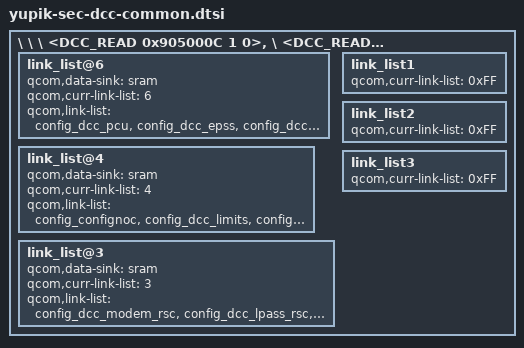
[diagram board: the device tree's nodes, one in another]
/* Copyright (c) 2019, The Linux Foundation. All rights reserved.
 *
 * This program is free software; you can redistribute it and/or modify
 * it under the terms of the GNU General Public License version 2 and
 * only version 2 as published by the Free Software Foundation.
 *
 * This program is distributed in the hope that it will be useful,
 * but WITHOUT ANY WARRANTY; without even the implied warranty of
 * MERCHANTABILITY or FITNESS FOR A PARTICULAR PURPOSE.  See the
 * GNU General Public License for more details.
 */

#include <dt-bindings/soc/qcom,dcc_v2.h>


#define config_dcc_pcu \
    /* PCU -DCC for LPM path */ \
    /*   Read only registers */ \
	<DCC_READ 0x18000010 1 0>, \
	<DCC_READ 0x18000024 1 0>, \
	<DCC_READ 0x18000038 6 0>, \
	<DCC_READ 0x18010010 1 0>, \
	<DCC_READ 0x18010024 1 0>, \
	<DCC_READ 0x18010038 6 0>, \
	<DCC_READ 0x18020010 1 0>, \
	<DCC_READ 0x18020024 1 0>, \
	<DCC_READ 0x18020038 6 0>, \
	<DCC_READ 0x18030010 1 0>, \
	<DCC_READ 0x18030024 1 0>, \
	<DCC_READ 0x18030038 6 0>, \
	<DCC_READ 0x18040010 1 0>, \
	<DCC_READ 0x18040024 1 0>, \
	<DCC_READ 0x18040038 6 0>, \
	<DCC_READ 0x18050010 1 0>, \
	<DCC_READ 0x18050024 1 0>, \
	<DCC_READ 0x18050038 6 0>, \
	<DCC_READ 0x18060010 1 0>, \
	<DCC_READ 0x18060024 1 0>, \
	<DCC_READ 0x18060038 6 0>, \
	<DCC_READ 0x18070010 1 0>, \
	<DCC_READ 0x18070024 1 0>, \
	<DCC_READ 0x18070038 6 0>, \
	<DCC_READ 0x18080010 1 0>, \
	<DCC_READ 0x18080024 1 0>, \
	<DCC_READ 0x18080038 6 0>, \
	<DCC_READ 0x1808006C 5 0>, \
	<DCC_READ 0x18080084 1 0>, \
	<DCC_READ 0x180800F4 1 0>, \
	<DCC_READ 0x180800F8 1 0>, \
	<DCC_READ 0x180800FC 1 0>, \
	<DCC_READ 0x18080100 12 0>, \
	<DCC_READ 0x18080130 3 0>, \
	<DCC_READ 0x18080158 1 0>, \
	<DCC_READ 0x1808015C 1 0>, \
	<DCC_READ 0x18080160 1 0>, \
	<DCC_READ 0x18080164 1 0>, \
	<DCC_READ 0x18080168 1 0>, \
	<DCC_READ 0x18080170 1 0>, \
	<DCC_READ 0x18080174 1 0>, \
	<DCC_READ 0x18080188 1 0>, \
	<DCC_READ 0x1808018C 1 0>, \
	<DCC_READ 0x18080190 1 0>, \
	<DCC_READ 0x18080194 1 0>, \
	<DCC_READ 0x18080198 1 0>, \
	<DCC_READ 0x180801AC 1 0>, \
	<DCC_READ 0x180801B0 4 0>, \
	<DCC_READ 0x180801C0 1 0>, \
	<DCC_READ 0x180801C8 1 0>, \
	<DCC_READ 0x180801F0 1 0>

#define config_dcc_epss  \
    /* EPSS clockdom Registers */ \
	<DCC_READ 0x18598020 1 0>, \
	<DCC_READ 0x1859001C 1 0>, \
	<DCC_READ 0x18590020 1 0>, \
	<DCC_READ 0x1859002C 1 0>, \
	<DCC_READ 0x18590064 1 0>, \
	<DCC_READ 0x18590068 1 0>, \
	<DCC_READ 0x1859006C 1 0>, \
	<DCC_READ 0x18590070 3 0>, \
	<DCC_READ 0x1859008C 1 0>, \
	<DCC_READ 0x185900DC 1 0>, \
	<DCC_READ 0x185900E8 1 0>, \
	<DCC_READ 0x185900EC 1 0>, \
	<DCC_READ 0x185900F0 1 0>, \
	<DCC_READ 0x18590300 1 0>, \
	<DCC_READ 0x1859030C 1 0>, \
	<DCC_READ 0x18590320 1 0>, \
	<DCC_READ 0x1859034C 1 0>, \
	<DCC_READ 0x185903BC 1 0>, \
	<DCC_READ 0x185903C0 1 0>, \
	<DCC_READ 0x1859101C 1 0>, \
	<DCC_READ 0x18591020 1 0>, \
	<DCC_READ 0x1859102C 1 0>, \
	<DCC_READ 0x18591064 1 0>, \
	<DCC_READ 0x18591068 1 0>, \
	<DCC_READ 0x1859106C 1 0>, \
	<DCC_READ 0x18591070 1 0>, \
	<DCC_READ 0x18591074 1 0>, \
	<DCC_READ 0x18591078 1 0>, \
	<DCC_READ 0x1859108C 1 0>, \
	<DCC_READ 0x185910DC 1 0>, \
	<DCC_READ 0x185910E8 1 0>, \
	<DCC_READ 0x185910EC 1 0>, \
	<DCC_READ 0x185910F0 1 0>, \
	<DCC_READ 0x18591300 1 0>, \
	<DCC_READ 0x1859130C 1 0>, \
	<DCC_READ 0x18591320 1 0>, \
	<DCC_READ 0x1859134C 1 0>, \
	<DCC_READ 0x185913BC 1 0>, \
	<DCC_READ 0x185913C0 1 0>, \
	<DCC_READ 0x1859201C 1 0>, \
	<DCC_READ 0x18592020 1 0>, \
	<DCC_READ 0x1859202C 1 0>, \
	<DCC_READ 0x18592064 1 0>, \
	<DCC_READ 0x18592068 1 0>, \
	<DCC_READ 0x1859206C 1 0>, \
	<DCC_READ 0x18592070 1 0>, \
	<DCC_READ 0x18592074 1 0>, \
	<DCC_READ 0x18592078 1 0>, \
	<DCC_READ 0x1859208C 1 0>, \
	<DCC_READ 0x185920DC 1 0>, \
	<DCC_READ 0x185920E8 1 0>, \
	<DCC_READ 0x185920EC 1 0>, \
	<DCC_READ 0x185920F0 1 0>, \
	<DCC_READ 0x18592300 1 0>, \
	<DCC_READ 0x1859230C 1 0>, \
	<DCC_READ 0x18592320 1 0>, \
	<DCC_READ 0x1859234C 1 0>, \
	<DCC_READ 0x185923BC 1 0>, \
	<DCC_READ 0x185923C0 1 0>, \
	<DCC_READ 0x1859301C 1 0>, \
	<DCC_READ 0x18593020 1 0>, \
	<DCC_READ 0x18593064 1 0>, \
	<DCC_READ 0x18593068 1 0>, \
	<DCC_READ 0x1859306C 1 0>, \
	<DCC_READ 0x18593070 1 0>, \
	<DCC_READ 0x18593074 1 0>, \
	<DCC_READ 0x18593078 1 0>, \
	<DCC_READ 0x1859308C 1 0>, \
	<DCC_READ 0x185930DC 1 0>, \
	<DCC_READ 0x185930E8 1 0>, \
	<DCC_READ 0x185930EC 1 0>, \
	<DCC_READ 0x185930F0 1 0>, \
	<DCC_READ 0x18593300 1 0>, \
	<DCC_READ 0x1859330C 1 0>, \
	<DCC_READ 0x18593320 1 0>, \
	<DCC_READ 0x1859302C 1 0>, \
	<DCC_READ 0x1859334C 1 0>, \
	<DCC_READ 0x185933BC 1 0>, \
	<DCC_READ 0x185933C0 1 0>, \
	<DCC_READ 0x18300000 1 0>, \
	<DCC_READ 0x1830000C 1 0>, \
	<DCC_READ 0x18300018 1 0>, \
	<DCC_READ 0x17C21000 2 0>, \
	<DCC_READ 0x18393A84 2 0>, \
	<DCC_READ 0x183A3A84 2 0>, \
    /* PLL_L_VAL */ \
	<DCC_READ 0x18280000 2 0>, \
	<DCC_READ 0x18282000 2 0>, \
	<DCC_READ 0x18284000 2 0>, \
	<DCC_READ 0x18286000 2 0>, \
	<DCC_READ 0x18300000 1 0>, \
    /* RSC -DCC for LPM path */ \
	<DCC_READ 0x18200400 3 0>, \
	<DCC_READ 0x18200038 1 0>, \
	<DCC_READ 0x18200040 1 0>, \
	<DCC_READ 0x18200048 1 0>, \
	<DCC_READ 0x18220038 1 0>, \
	<DCC_READ 0x18220040 1 0>, \
	<DCC_READ 0x182200D0 1 0>, \
	<DCC_READ 0x18200030 1 0>, \
	<DCC_READ 0x18200010 1 0>

#define config_dcc_pimem \
	<DCC_READ 0x610100 11 0>

#define config_dcc_core \
    /*  core hang */ \
	<DCC_READ 0x18000058 1 0>, \
	<DCC_READ 0x1800005C 1 0>, \
	<DCC_READ 0x18000060 1 0>, \
	<DCC_READ 0x18000064 1 0>, \
	<DCC_READ 0x1800006C 1 0>, \
	<DCC_READ 0x180000F0 2 0>, \
	<DCC_READ 0x18010058 1 0>, \
	<DCC_READ 0x1801005C 1 0>, \
	<DCC_READ 0x18010060 1 0>, \
	<DCC_READ 0x18010064 1 0>, \
	<DCC_READ 0x1801006C 1 0>, \
	<DCC_READ 0x180100F0 2 0>, \
	<DCC_READ 0x18020058 1 0>, \
	<DCC_READ 0x1802005C 1 0>, \
	<DCC_READ 0x18020060 1 0>, \
	<DCC_READ 0x18020064 1 0>, \
	<DCC_READ 0x1802006C 1 0>, \
	<DCC_READ 0x180200F0 2 0>, \
	<DCC_READ 0x18030058 1 0>, \
	<DCC_READ 0x1803005C 1 0>, \
	<DCC_READ 0x18030060 1 0>, \
	<DCC_READ 0x18030064 1 0>, \
	<DCC_READ 0x1803006C 1 0>, \
	<DCC_READ 0x180300F0 2 0>, \
	<DCC_READ 0x18040058 1 0>, \
	<DCC_READ 0x1804005C 1 0>, \
	<DCC_READ 0x18040060 1 0>, \
	<DCC_READ 0x18040064 1 0>, \
	<DCC_READ 0x1804006C 1 0>, \
	<DCC_READ 0x180400F0 2 0>, \
	<DCC_READ 0x18050058 1 0>, \
	<DCC_READ 0x1805005C 1 0>, \
	<DCC_READ 0x18050060 1 0>, \
	<DCC_READ 0x18050064 1 0>, \
	<DCC_READ 0x1805006C 1 0>, \
	<DCC_READ 0x180500F0 2 0>, \
	<DCC_READ 0x18060058 1 0>, \
	<DCC_READ 0x1806005C 1 0>, \
	<DCC_READ 0x18060060 1 0>, \
	<DCC_READ 0x18060064 1 0>, \
	<DCC_READ 0x1806006C 1 0>, \
	<DCC_READ 0x180600F0 2 0>, \
	<DCC_READ 0x18070058 1 0>, \
	<DCC_READ 0x1807005C 1 0>, \
	<DCC_READ 0x18070060 1 0>, \
	<DCC_READ 0x18070064 1 0>, \
	<DCC_READ 0x1807006C 1 0>, \
	<DCC_READ 0x180700F0 2 0>, \
    /* CPRh */ \
	<DCC_READ 0x18101908 1 0>, \
	<DCC_READ 0x18101C18 1 0>, \
	<DCC_READ 0x18390810 1 0>, \
	<DCC_READ 0x18390C50 1 0>, \
	<DCC_READ 0x18390814 1 0>, \
	<DCC_READ 0x18390C54 1 0>, \
	<DCC_READ 0x18390818 1 0>, \
	<DCC_READ 0x18390C58 1 0>, \
	<DCC_READ 0x18393A84 2 0>, \
	<DCC_READ 0x18100908 1 0>, \
	<DCC_READ 0x18100C18 1 0>, \
	<DCC_READ 0x183A0810 1 0>, \
	<DCC_READ 0x183A0C50 1 0>, \
	<DCC_READ 0x183A0814 1 0>, \
	<DCC_READ 0x183A0C54 1 0>, \
	<DCC_READ 0x183A0818 1 0>, \
	<DCC_READ 0x183A0C58 1 0>, \
	<DCC_READ 0x183A3A84 2 0>, \
	<DCC_READ 0x18393500 1 0>, \
	<DCC_READ 0x18393580 1 0>, \
	<DCC_READ 0x183A3500 1 0>, \
	<DCC_READ 0x183A3580 1 0>, \
    /* Gold PLL */ \
	<DCC_READ 0x18282000 4 0>, \
	<DCC_READ 0x18282028 1 0>, \
	<DCC_READ 0x18282038 1 0>, \
	<DCC_READ 0x18282080 5 0>, \
	<DCC_READ 0x18286000 4 0>, \
	<DCC_READ 0x18286028 1 0>, \
	<DCC_READ 0x18286038 1 0>, \
	<DCC_READ 0x18286080 5 0>, \
    /* rpmh */ \
	<DCC_READ 0x0C201244 1 0>, \
	<DCC_READ 0x0C202244 1 0>, \
	<DCC_READ 0x18300000 1 0>, \
    /* GOLD */ \
	<DCC_READ 0x1829208C 1 0>, \
	<DCC_READ 0x18292098 1 0>, \
	<DCC_READ 0x18292098 1 0>, \
    /* GOLD+ */ \
	<DCC_READ 0x1829608C 1 0>, \
	<DCC_READ 0x18296098 1 0>, \
	<DCC_READ 0x18296098 1 0>, \
  /* Security Control Core for Binning info */ \
	<DCC_READ 0x00784184 1 0>

#define config_dcc_gemnoc \
    /* Dump Coherent even debug chain */ \
	<DCC_READ 0x9103008 1 0>, \
	<DCC_LOOP 0x5 0 0>, \
	<DCC_READ 0x9103010 1 0>, \
	<DCC_READ 0x9103014 1 0>, \
	<DCC_LOOP 0x1 0 0>, \
    /* Dump Non-Coherent Even Chain debug */ \
	<DCC_READ 0x9103408 1 0>, \
	<DCC_LOOP 0x5 0 0>, \
	<DCC_READ 0x9103410 1 0>, \
	<DCC_READ 0x9103414 1 0>, \
	<DCC_LOOP 0x1 0 0>, \
    /*  Dump Coherent Odd Chain debug */ \
	<DCC_READ 0x9143008 1 0>, \
	<DCC_LOOP 0x5 0 0>, \
	<DCC_READ 0x9143010 1 0>, \
	<DCC_READ 0x9143014 1 0>, \
	<DCC_LOOP 0x1 0 0>, \
    /*  Dump Non-Coherent Odd Chain debug */ \
	<DCC_READ 0x9143408 1 0>, \
	<DCC_LOOP 0x5 0 0>, \
	<DCC_READ 0x9143410 1 0>, \
	<DCC_READ 0x9143414 1 0>, \
	<DCC_LOOP 0x1 0 0>, \
    /*  Dump Coherent Sys Chain debug */ \
	<DCC_READ 0x91B0008 1 0>, \
	<DCC_LOOP 0x3 0 0>, \
	<DCC_READ 0x91B0010 1 0>, \
	<DCC_READ 0x91B0014 1 0>, \
	<DCC_LOOP 0x1 0 0>, \
    /*  Dump Non-Coherent Sys Chain debug */ \
	<DCC_READ 0x91B1008 1 0>, \
	<DCC_LOOP 0x10 0 0>, \
	<DCC_READ 0x91B1010 1 0>, \
	<DCC_READ 0x91B1014 1 0>, \
	<DCC_LOOP 0x1 0 0>, \
    /*  llcc0 pos debug Info dump */ \
	<DCC_READ 0x9101808 1 0>, \
	<DCC_READ 0x910180C 1 0>, \
    /*  llcc0 pos Context Table Info dump - Retrieve context information */ \
	<DCC_WRITE 0x9101828 0x00000001 1>, \
	<DCC_LOOP 0x41 0 0>, \
	<DCC_READ 0x9101810 1 0>, \
	<DCC_READ 0x9101814 1 0>, \
	<DCC_READ 0x9101818 1 0>, \
	<DCC_READ 0x910181C 1 0>, \
	<DCC_LOOP 0x1 0 0>, \
    /*  llcc1 pos debug info dump */ \
	<DCC_READ 0x9141808 1 0>, \
	<DCC_READ 0x914180C 1 0>, \
    /*  llcc1 pos Context Table Info dump - Retrieve context information */ \
	<DCC_WRITE 0x9141828 0x00000001 1>, \
	<DCC_LOOP 0x41 0 0>, \
	<DCC_READ 0x9141810 1 0>, \
	<DCC_READ 0x9141814 1 0>, \
	<DCC_READ 0x9141818 1 0>, \
	<DCC_READ 0x914181C 1 0>, \
	<DCC_LOOP 0x1 0 0>, \
    /*  PCIe pos debug info dump */ \
	<DCC_READ 0x91A8008 1 0>, \
	<DCC_READ 0x91A800C 1 0>, \
    /*  PCIe pos Context Table Info dump - Retrieve context information */ \
	<DCC_WRITE 0x91A8028 0x00000001 1>, \
	<DCC_LOOP 0x11 0 0>, \
	<DCC_READ 0x91A8010 1 0>, \
	<DCC_READ 0x91A8014 1 0>, \
	<DCC_READ 0x91A8018 1 0>, \
	<DCC_READ 0x91A801C 1 0>, \
	<DCC_LOOP 0x1 0 0>, \
    /*  SNoC pos debug info dump */ \
	<DCC_READ 0x91A8808 1 0>, \
	<DCC_READ 0x91A880C 1 0>, \
    /*  SNoC pos Context Table Info dump - Retrieve context information */ \
	<DCC_WRITE 0x91A8828 0x00000001 1>, \
	<DCC_LOOP 0x11 0 0>, \
	<DCC_READ 0x91A8810 1 0>, \
	<DCC_READ 0x91A8814 1 0>, \
	<DCC_READ 0x91A8818 1 0>, \
	<DCC_READ 0x91A881C 1 0>, \
	<DCC_LOOP 0x1 0 0>, \
    /* GEMNOC Err Log registers */ \
	<DCC_READ 0x9100000 1 0>, \
	<DCC_READ 0x9100008 1 0>, \
	<DCC_READ 0x910000C 1 0>, \
	<DCC_READ 0x9140000 1 0>, \
	<DCC_READ 0x9140008 1 0>, \
	<DCC_READ 0x914000C 1 0>, \
	<DCC_READ 0x9180000 1 0>, \
	<DCC_READ 0x9180008 1 0>, \
	<DCC_READ 0x918000C 1 0>, \
	<DCC_READ 0x9180404 1 0>, \
	<DCC_READ 0x9180408 1 0>, \
	<DCC_READ 0x918040C 1 0>, \
	<DCC_READ 0x9181010 1 0>, \
	<DCC_READ 0x9181020 8 0>, \
	<DCC_READ 0x91E1048 1 0>, \
	<DCC_READ 0x9121010 1 0>, \
	<DCC_READ 0x9122010 1 0>, \
	<DCC_READ 0x9123010 1 0>, \
	<DCC_READ 0x9125010 1 0>, \
	<DCC_READ 0x9161010 1 0>, \
	<DCC_READ 0x9162010 1 0>, \
	<DCC_READ 0x9163010 1 0>, \
	<DCC_READ 0x9165010 1 0>, \
	<DCC_READ 0x91CF010 1 0>, \
	<DCC_READ 0x91D0010 1 0>, \
	<DCC_READ 0x91D1010 1 0>, \
	<DCC_READ 0x91D2010 1 0>, \
	<DCC_READ 0x91D3010 1 0>, \
	<DCC_READ 0x91D4010 1 0>, \
	<DCC_READ 0x91D5010 1 0>, \
	<DCC_READ 0x91D6010 1 0>, \
	<DCC_READ 0x91D7010 1 0>, \
	<DCC_READ 0x9101408 1 0>, \
	<DCC_READ 0x9141410 1 0>, \
	<DCC_READ 0x9100810 1 0>, \
	<DCC_READ 0x9140810 1 0>, \
	<DCC_READ 0x9100820 1 0>, \
	<DCC_READ 0x9140820 1 0>, \
	<DCC_READ 0x9100828 1 0>, \
	<DCC_READ 0x910082C 1 0>, \
	<DCC_READ 0x9140828 1 0>, \
	<DCC_READ 0x914082C 1 0>
    /* GemNOC for YUPIK end */ \

#define config_dcc_tsens \
    /* TSENS0 TEST_CTRL Register */ \
	<DCC_READ 0x0C222004 1 0>, \
    /* TSENS0 Critical INT Status Register */ \
	<DCC_READ 0x0C263014 1 0>, \
    /* TSENS0 0C INT Status Register */ \
	<DCC_READ 0x0C2630E0 1 0>, \
    /* TSENS0 MIN_TEMP Register */ \
	<DCC_READ 0x0C2630EC 1 0>, \
    /* TSENS0 16 sensor status Register */ \
	<DCC_READ 0x0C2630A0 16 0>, \
    /* TSENS0 MAX_TEMP Register */ \
	<DCC_READ 0x0C2630E8 1 0>, \
    /* TSENS0 WatchDog log Register */ \
	<DCC_READ 0x0C26313C 1 0>, \
    /* TSENS1 TEST_CTRL Register */ \
	<DCC_READ 0x0C223004 1 0>, \
    /* TSENS1 Critical INT Status Register */ \
	<DCC_READ 0x0C265014 1 0>, \
    /* TSENS1 0C INT Status Register */ \
	<DCC_READ 0x0C2650E0 1 0>, \
    /* TSENS1 MIN_TEMP Register */ \
	<DCC_READ 0x0C2650EC 1 0>, \
    /* TSENS1 16 sensor status Register */ \
	<DCC_READ 0x0C2650A0 16 0>, \
    /* TSENS1 MAX_TEMP Register */ \
	<DCC_READ 0x0C2650E8 1 0>, \
    /* TSENS1 WatchDog log Register */ \
	<DCC_READ 0x0C26513C 1 0>

#define config_dcc_spmi  \
	<DCC_READ 0xC410000 1 0>, \
	<DCC_READ 0xC40AF04 1 0>, \
	<DCC_READ 0xC40AF10 1 0>, \
	<DCC_READ 0xC40A000 1 0>, \
	<DCC_READ 0xC40A018 1 0>, \
	<DCC_READ 0xC40A028 1 0>, \
	<DCC_READ 0xC40A02C 1 0>, \
	<DCC_READ 0xC40A100 1 0>, \
	<DCC_READ 0xC2A22FC 1 0>, \
	<DCC_READ 0xC2A2300 1 0>, \
	<DCC_READ 0xC2A2304 1 0>, \
    /* PMIC ARB registers */ \
	<DCC_READ 0xC440200 1 0>, \
	<DCC_READ 0xC440204 1 0>, \
	<DCC_READ 0xC442200 1 0>, \
	<DCC_READ 0xC442204 1 0>, \
	<DCC_READ 0xC442208 1 0>, \
	<DCC_READ 0xC44220C 1 0>

#define config_dcc_gpu \
    /* GPUCC Registers */ \
	<DCC_READ 0x3D9100C 1 0>, \
	<DCC_READ 0x3D91010 2 0>, \
	<DCC_READ 0x3D9106C 3 0>, \
	<DCC_READ 0x3D91004 1 0>, \
	<DCC_READ 0x3D91054 3 0>, \
	<DCC_READ 0x3D91060 2 0>, \
	<DCC_READ 0x3D91070 2 0>, \
	<DCC_READ 0x3D91080 3 0>, \
	<DCC_READ 0x3D91078 2 0>, \
	<DCC_READ 0x3D9108C 1 0>, \
	<DCC_READ 0x3D91090 1 0>, \
	<DCC_READ 0x3D91098 2 0>, \
	<DCC_READ 0x3D910A4 2 0>, \
	<DCC_READ 0x3D910F0 2 0>, \
	<DCC_READ 0x3D91100 1 0>, \
	<DCC_READ 0x3D91118 1 0>, \
	<DCC_READ 0x3D91164 2 0>, \
	<DCC_READ 0x3D91170 1 0>, \
	<DCC_READ 0x3D91178 1 0>, \
	<DCC_READ 0x3D91204 1 0>, \
	<DCC_READ 0x3D9120C 1 0>, \
	<DCC_READ 0x3D98024 1 0>, \
	<DCC_READ 0x3D9802C 1 0>, \
	<DCC_READ 0x3D98030 1 0>, \
	<DCC_READ 0x3D92000 2 0>, \
	<DCC_READ 0x3D93000 2 0>, \
	<DCC_READ 0x3D95000 2 0>, \
	<DCC_READ 0x3D96000 2 0>, \
	<DCC_READ 0x3D97000 2 0>, \
    /* GPU GCC Registers */ \
	<DCC_READ 0x119000 1 0>, \
	<DCC_READ 0x11903C 1 0>, \
	<DCC_READ 0x171004 2 0>, \
	<DCC_READ 0x17100C 1 0>, \
	<DCC_READ 0x171014 1 0>, \
	<DCC_READ 0x171018 1 0>, \
	<DCC_READ 0x171154 1 0>, \
	<DCC_READ 0x171158 1 0>, \
	<DCC_READ 0x17115C 1 0>, \
	<DCC_READ 0x17A04C 1 0>, \
	<DCC_READ 0x17B000 1 0>, \
	<DCC_READ 0x17B03C 1 0>, \
	<DCC_READ 0x17C000 1 0>, \
	<DCC_READ 0x17C03C 1 0>, \
	<DCC_READ 0x17D000 1 0>, \
	<DCC_READ 0x17D03C 1 0>, \
	<DCC_READ 0x17E000 1 0>, \
	<DCC_READ 0x17E03C 1 0>, \
	<DCC_READ 0x187000 1 0>, \
	<DCC_READ 0x18703C 1 0>, \
	<DCC_READ 0x3D91534 1 0>, \
	<DCC_READ 0x3D002B4 1 0>, \
	<DCC_READ 0x3D00410 2 0>, \
	<DCC_READ 0x3D00818 1 0>, \
	<DCC_READ 0x3D7E220 2 0>

#define config_sysnoc \
    /* system_noc_main_erl_Err */ \
	<DCC_READ 0x1680000 1 0>, \
	<DCC_READ 0x1680008 1 0>, \
	<DCC_READ 0x1680010 1 0>, \
	<DCC_READ 0x1680020 8 0>, \
    /* system_noc_main_FaultInStatus */ \
	<DCC_READ 0x1680248 1 0>, \
	<DCC_READ 0x1680B00 6 0>

#define config_aggrenoc \
    /*  AGGRE_NOC debug chains */ \
    /*  Dump South Chain debug */ \
	<DCC_READ 0x16E4008 1 0>, \
	<DCC_LOOP 4 0 0>, \
	<DCC_READ 0x16E4010 1 0>, \
	<DCC_READ 0x16E4014 1 0>, \
	<DCC_LOOP 1 0 0>, \
    /*  Dump Center Chain debug */ \
	<DCC_READ 0x1706208 1 0>, \
	<DCC_LOOP 4 0 0>, \
	<DCC_READ 0x1706210 1 0>, \
	<DCC_READ 0x1706214 1 0>, \
	<DCC_LOOP 1 0 0>, \
    /* aggre_noc_a1noc_ErrorLogger */ \
	<DCC_READ 0x16E0000 1 0>, \
	<DCC_READ 0x16E0010 1 0>, \
	<DCC_READ 0x16E0008 1 0>, \
	<DCC_READ 0x16E0020 8 0>, \
    /* aggre_noc_a1noc_FaultInStatus */ \
	<DCC_READ 0x16E5048 1 0>, \
	<DCC_READ 0x16E5248 1 0>, \
	<DCC_READ 0x16E5448 1 0>, \
    /* A1NOC SENSEIN Registers */ \
	<DCC_READ 0x16E5100 5 0>, \
	<DCC_READ 0x16E5300 2 0>, \
	<DCC_READ 0x16E5500 2 0>, \
    /* aggre_noc_a2noc_ErrorLogger */ \
	<DCC_READ 0x1700000 1 0>, \
	<DCC_READ 0x1700008 1 0>, \
	<DCC_READ 0x1700010 1 0>, \
	<DCC_READ 0x1700020 8 0>, \
    /* A2NOC SENSEIN registers */ \
	<DCC_READ 0x170B100 5 0>, \
    /* aggre_noc_a2noc_FaultInStatus */ \
	<DCC_READ 0x170B048 1 0>

#define config_dcc_gcc \
	<DCC_READ 0x100000 15 0>, \
	<DCC_READ 0x101000 15 0>, \
	<DCC_READ 0x176000 15 0>, \
	<DCC_READ 0x174000 15 0>, \
	<DCC_READ 0x113000 15 0>, \
	<DCC_READ 0x11A000 15 0>, \
	<DCC_READ 0x11C000 15 0>, \
	<DCC_READ 0x11C048 3 0>, \
	<DCC_READ 0x11E000 15 0>, \
	<DCC_READ 0x10401C 1 0>, \
	<DCC_READ 0x105074 1 0>, \
	<DCC_READ 0x183024 1 0>, \
	<DCC_READ 0x109050 1 0>, \
	<DCC_READ 0x123020 1 0>, \
	<DCC_READ 0x117024 1 0>, \
	<DCC_READ 0x117154 1 0>, \
	<DCC_READ 0x117284 1 0>, \
	<DCC_READ 0x1173B4 1 0>, \
	<DCC_READ 0x1174E4 1 0>, \
	<DCC_READ 0x117614 1 0>, \
	<DCC_READ 0x117744 1 0>, \
	<DCC_READ 0x117874 1 0>, \
	<DCC_READ 0x118024 1 0>, \
	<DCC_READ 0x118154 1 0>, \
	<DCC_READ 0x118284 1 0>, \
	<DCC_READ 0x1183B4 1 0>, \
	<DCC_READ 0x1184E4 1 0>, \
	<DCC_READ 0x118614 1 0>, \
	<DCC_READ 0x118744 1 0>, \
	<DCC_READ 0x118874 1 0>, \
	<DCC_READ 0x129020 1 0>, \
	<DCC_READ 0x11D020 1 0>, \
	<DCC_READ 0x134024 1 0>, \
	<DCC_READ 0x141024 1 0>, \
	<DCC_READ 0x14415C 1 0>, \
	<DCC_READ 0x14504C 1 0>, \
	<DCC_READ 0x18903C 1 0>, \
	<DCC_READ 0x151000 1 0>, \
	<DCC_READ 0x151008 1 0>, \
	<DCC_READ 0x151010 1 0>, \
	<DCC_READ 0x152000 1 0>, \
	<DCC_READ 0x152008 1 0>, \
	<DCC_READ 0x152010 1 0>, \
	<DCC_READ 0x153020 1 0>, \
	<DCC_READ 0x153028 1 0>, \
	<DCC_READ 0x153030 1 0>, \
	<DCC_READ 0x155000 1 0>, \
	<DCC_READ 0x155008 1 0>, \
	<DCC_READ 0x155010 1 0>, \
	<DCC_READ 0x15B000 1 0>, \
	<DCC_READ 0x15B008 1 0>, \
	<DCC_READ 0x15B010 1 0>, \
	<DCC_READ 0x157000 1 0>, \
	<DCC_READ 0x157008 1 0>, \
	<DCC_READ 0x157010 1 0>, \
	<DCC_READ 0x135020 1 0>, \
	<DCC_READ 0x135028 1 0>, \
	<DCC_READ 0x135030 1 0>, \
	<DCC_READ 0x156000 1 0>, \
	<DCC_READ 0x156008 1 0>, \
	<DCC_READ 0x156010 1 0>, \
	<DCC_READ 0x15A000 1 0>, \
	<DCC_READ 0x15A008 1 0>, \
	<DCC_READ 0x15A010 1 0>, \
	<DCC_READ 0x190004 1 0>, \
	<DCC_READ 0x109008 1 0>, \
	<DCC_READ 0x190010 1 0>, \
	<DCC_READ 0x190020 1 0>, \
	<DCC_READ 0x190028 1 0>, \
	<DCC_READ 0x109010 1 0>, \
	<DCC_READ 0x109018 1 0>, \
	<DCC_READ 0x109018 1 0>, \
	<DCC_READ 0x109020 1 0>, \
	<DCC_READ 0x18D080 1 0>, \
	<DCC_READ 0x145014 1 0>, \
	<DCC_READ 0x14501C 1 0>, \
	<DCC_READ 0x183004 1 0>, \
	<DCC_READ 0x183008 1 0>, \
	<DCC_READ 0x183140 1 0>, \
	<DCC_READ 0x171158 2 0>, \
	<DCC_READ 0x109004 3 0>, \
	<DCC_READ 0x109160 1 0>, \
	<DCC_READ 0x109468 1 0>, \
	<DCC_READ 0x10F004 3 0>, \
	<DCC_READ 0x145000 3 0>, \
	<DCC_READ 0x16B004 3 0>, \
	<DCC_READ 0x18D004 3 0>, \
	<DCC_READ 0x177004 3 0>, \
	<DCC_READ 0x189004 3 0>, \
	<DCC_READ 0x153000 9 0>, \
	<DCC_READ 0x135000 9 0>, \
	<DCC_READ 0x106100 1 0>, \
	<DCC_READ 0x147004 1 0>, \
	<DCC_READ 0x17B000 1 0>, \
	<DCC_READ 0x17B004 1 0>, \
	<DCC_READ 0x17B008 1 0>, \
	<DCC_READ 0x17B00C 1 0>, \
	<DCC_READ 0x17B010 1 0>, \
	<DCC_READ 0x17B014 1 0>, \
	<DCC_READ 0x17B018 1 0>, \
	<DCC_READ 0x17B01C 1 0>, \
	<DCC_READ 0x17B020 1 0>, \
	<DCC_READ 0x17B024 1 0>, \
	<DCC_READ 0x17B028 1 0>, \
	<DCC_READ 0x17B02C 1 0>, \
	<DCC_READ 0x17B03C 1 0>, \
	<DCC_READ 0x17B040 1 0>, \
	<DCC_READ 0x17B044 1 0>, \
	<DCC_READ 0x17B048 1 0>, \
	<DCC_READ 0x17B04C 1 0>, \
	<DCC_READ 0x17B050 1 0>, \
	<DCC_READ 0x17B054 1 0>, \
	<DCC_READ 0x17B058 1 0>, \
	<DCC_READ 0x17B05C 1 0>, \
	<DCC_READ 0x17B060 1 0>, \
	<DCC_READ 0x17B064 1 0>, \
	<DCC_READ 0x17B068 1 0>, \
	<DCC_READ 0x17C000 1 0>, \
	<DCC_READ 0x17C004 1 0>, \
	<DCC_READ 0x17C008 1 0>, \
	<DCC_READ 0x17C00C 1 0>, \
	<DCC_READ 0x17C010 1 0>, \
	<DCC_READ 0x17C014 1 0>, \
	<DCC_READ 0x17C018 1 0>, \
	<DCC_READ 0x17C01C 1 0>, \
	<DCC_READ 0x17C020 1 0>, \
	<DCC_READ 0x17C024 1 0>, \
	<DCC_READ 0x17C028 1 0>, \
	<DCC_READ 0x17C02C 1 0>, \
	<DCC_READ 0x17C03C 1 0>, \
	<DCC_READ 0x17C040 1 0>, \
	<DCC_READ 0x17C044 1 0>, \
	<DCC_READ 0x17C048 1 0>, \
	<DCC_READ 0x17C04C 1 0>, \
	<DCC_READ 0x17C050 1 0>, \
	<DCC_READ 0x17C054 1 0>, \
	<DCC_READ 0x17C058 1 0>, \
	<DCC_READ 0x17C05C 1 0>, \
	<DCC_READ 0x17C060 1 0>, \
	<DCC_READ 0x17C064 1 0>, \
	<DCC_READ 0x17C068 1 0>, \
	<DCC_READ 0x153124 1 0>, \
	<DCC_READ 0x156124 1 0>, \
	<DCC_READ 0x1453A4 1 0>, \
	<DCC_READ 0x182884 1 0>, \
	<DCC_READ 0x145384 1 0>, \
	<DCC_READ 0xC2A0000 15 0>, \
	<DCC_READ 0xC2A1000 15 0>, \
    /* SHUB RCGS */ \
	<DCC_READ 0x17101C 1 0>, \
	<DCC_READ 0x171020 1 0>, \
	<DCC_READ 0x14401C 1 0>, \
	<DCC_READ 0x144020 1 0>, \
	<DCC_READ 0x183010 1 0>, \
	<DCC_READ 0x183014 1 0>, \
	<DCC_READ 0x18A160 1 0>, \
	<DCC_READ 0x18A164 1 0>, \
	<DCC_READ 0x18A004 1 0>, \
	<DCC_READ 0x18A01C 1 0>, \
	<DCC_READ 0x18A020 1 0>, \
	<DCC_READ 0x18A024 1 0>, \
	<DCC_READ 0x19D004 1 0>, \
	<DCC_READ 0x19D008 1 0>, \
    /* FSM_SHUB_STATE */ \
	<DCC_READ 0x196100 1 0>, \
    /* GPLL STATE */ \
	<DCC_READ 0x10003C 1 0>, \
	<DCC_READ 0x10103C 1 0>, \
	<DCC_READ 0x10203C 1 0>, \
	<DCC_READ 0x10303C 1 0>, \
	<DCC_READ 0x11303C 1 0>, \
	<DCC_READ 0x11A03C 1 0>, \
	<DCC_READ 0x11C03C 1 0>, \
	<DCC_READ 0x17403C 1 0>, \
	<DCC_READ 0x17603C 1 0>, \
	<DCC_READ 0x11E03C 1 0>, \
    /* RPMH BCM STATUS */ \
	<DCC_READ 0xBBF0004 12 0>, \
	<DCC_READ 0xBBF0800 12 0>, \
	<DCC_READ 0xBBF0004 12 0>, \
	<DCC_READ 0xBBF0800 12 0>

#define config_confignoc \
    /*  CONFIG_NOC debug chains */ \
    /*  Dump Center Chain debug */ \
	<DCC_READ 0x01510008 1 0>, \
	<DCC_LOOP 9 0 0>, \
	<DCC_READ 0x151D010 1 0>, \
	<DCC_READ 0x151D014 1 0>, \
	<DCC_LOOP 1 0 0>, \
	<DCC_LOOP 9 0 0>, \
	<DCC_READ 0x1506010 1 0>, \
	<DCC_READ 0x1506014 1 0>, \
	<DCC_LOOP 1 0 0>, \
    /*  Dump east Chain debug */ \
	<DCC_READ 0x151D208 1 0>, \
	<DCC_READ 0x1507008 1 0>, \
	<DCC_LOOP 2 0 0>, \
	<DCC_READ 0x151D210 1 0>, \
	<DCC_READ 0x151D214 1 0>, \
	<DCC_LOOP 1 0 0>, \
	<DCC_LOOP 2 0 0>, \
	<DCC_READ 0x1507010 1 0>, \
	<DCC_READ 0x1507014 1 0>, \
	<DCC_LOOP 1 0 0>, \
    /*  Dump South Chain debug */ \
	<DCC_READ 0x151D308 1 0>, \
	<DCC_READ 0x1509008 1 0>, \
	<DCC_LOOP 3 0 0>, \
	<DCC_READ 0x1509010 1 0>, \
	<DCC_READ 0x1509014 1 0>, \
	<DCC_LOOP 1 0 0>, \
	<DCC_LOOP 3 0 0>, \
	<DCC_READ 0x151D310 1 0>, \
	<DCC_READ 0x151D314 1 0>, \
	<DCC_LOOP 1 0 0>, \
    /*  config_noc_lpass region */ \
	<DCC_READ 0x01514008 1 0>, \
	<DCC_LOOP 3 0 0>, \
	<DCC_READ 0x01514010 1 0>, \
	<DCC_LOOP 1 0 0>, \
    /* config_noc_erl_Err */ \
	<DCC_READ 0x1500000 1 0>, \
	<DCC_READ 0x1510000 1 0>, \
	<DCC_READ 0x1500010 1 0>, \
	<DCC_READ 0x1510010 1 0>, \
	<DCC_READ 0x1500020 8 0>, \
	<DCC_READ 0x1510020 8 0>, \
    /* config_noc_timeout_fault_sbm_FaultInStatus */ \
	<DCC_READ 0x1511048 1 0>, \
	<DCC_READ 0x1501048 2 0>, \
	<DCC_READ 0x1501058 1 0>, \
	<DCC_READ 0x1501248 1 0>, \
	<DCC_READ 0x1511248 1 0>, \
    /* config_noc_main_fault_sbm_FaultInStatus */ \
	<DCC_READ 0x1501248 1 0>, \
    /* config_noc_center_niu_status0 sensein */ \
	<DCC_READ 0x1511B00 1 0>, \
	<DCC_READ 0x151E100 1 0>, \
	<DCC_READ 0x150B100 1 0>

#define config_dcc_limits \
    /* central broadcast */ \
	<DCC_READ 0xEC80004 1 0>, \
	<DCC_READ 0xEC80058 1 0>, \
	<DCC_READ 0xEC80060 8 0>, \
	<DCC_READ 0xEC800A0 8 0>, \
	<DCC_READ 0xEC800C0 16 0>, \
	<DCC_READ 0xEC80100 16 0>, \
    /* RPDM */ \
	<DCC_READ 0x634008 1 0>, \
	<DCC_READ 0x634F00 8 0>, \
	<DCC_READ 0x635560 1 0>, \
	<DCC_READ 0x635570 1 0>, \
	<DCC_READ 0x635580 1 0>, \
	<DCC_READ 0x635590 1 0>, \
	<DCC_READ 0x6355A0 4 0>, \
	<DCC_READ 0x635600 1 0>, \
	<DCC_READ 0x635610 1 0>, \
	<DCC_READ 0x636008 1 0>, \
	<DCC_READ 0x636F00 8 0>, \
	<DCC_READ 0x637560 1 0>, \
	<DCC_READ 0x637570 1 0>, \
	<DCC_READ 0x637580 1 0>, \
	<DCC_READ 0x637590 1 0>, \
	<DCC_READ 0x6375A0 4 0>, \
	<DCC_READ 0x637600 1 0>, \
	<DCC_READ 0x637610 1 0>, \
    /* GOLD LLM */ \
	<DCC_READ 0x18370220 2 0>, \
	<DCC_READ 0x183702A0 2 0>, \
	<DCC_READ 0x183704A0 12 0>, \
	<DCC_READ 0x18370520 1 0>, \
	<DCC_READ 0x18370588 1 0>, \
	<DCC_READ 0x18370D10 12 0>, \
	<DCC_READ 0x18370F90 10 0>, \
	<DCC_READ 0x18371010 10 0>, \
	<DCC_READ 0x18371A10 8 0>, \
    /* silver LLM */ \
	<DCC_READ 0x183784A0 12 0>, \
	<DCC_READ 0x18378520 1 0>, \
	<DCC_READ 0x18378588 1 0>, \
	<DCC_READ 0x18378D10 8 0>, \
	<DCC_READ 0x18378F90 6 0>, \
	<DCC_READ 0x18379010 6 0>, \
	<DCC_READ 0x18379A10 4 0>, \
    /* Turing LLM */ \
	<DCC_READ 0xA310220 3 0>, \
	<DCC_READ 0xA3102A0 3 0>, \
	<DCC_READ 0xA3104A0 6 0>, \
	<DCC_READ 0xA310520 1 0>, \
	<DCC_READ 0xA310588 1 0>, \
	<DCC_READ 0xA310D10 8 0>, \
	<DCC_READ 0xA310F90 6 0>, \
	<DCC_READ 0xA311010 6 0>, \
	<DCC_READ 0xA311A10 3 0>

#define config_dcc_gic \
	<DCC_READ 0x17A00104 29 0>, \
	<DCC_READ 0x17A00204 29 0>

#define config_mmssnoc  \
    /*  MMSS_NOC debug chains */ \
    /*  Dump Chain debug */ \
	<DCC_READ 0x01741008 1 0>, \
	<DCC_LOOP 9 0 0>, \
	<DCC_READ 0x01741010 1 0>, \
	<DCC_READ 0x01741014 1 0>, \
	<DCC_LOOP 1 0 0>, \
    /* mmss_noc_erl_Err */ \
	<DCC_READ 0x1740000 1 0>, \
	<DCC_READ 0x1740008 1 0>, \
	<DCC_READ 0x1740010 1 0>, \
	<DCC_READ 0x1740020 8 0>, \
    /* mmss_noc_sbm_FaultInStatus */ \
	<DCC_READ 0x174B048 1 0>, \
    /* mmss NOC SENSEIN */ \
	<DCC_READ 0x174B100 8 0>, \
    /* DC_noc SENSEIN */ \
	<DCC_READ 0x90E0000 1 0>, \
	<DCC_READ 0x90E0008 1 0>, \
	<DCC_READ 0x90E0010 1 0>, \
	<DCC_READ 0x90E0020 8 0>, \
	<DCC_READ 0x90E0248 1 0>, \
	<DCC_READ 0x90E3100 1 0>, \
	<DCC_READ 0x90E4100 7 0>, \
    /* mmss noc qos gen regs */ \
	<DCC_READ 0x1750010 1 0>, \
	<DCC_READ 0x1750190 1 0>, \
	<DCC_READ 0x1751010 1 0>, \
	<DCC_READ 0x1752010 1 0>, \
	<DCC_READ 0x1754010 1 0>, \
	<DCC_READ 0x1755010 1 0>, \
	<DCC_READ 0x1756010 1 0>, \
	<DCC_READ 0x1758010 1 0>, \
	<DCC_READ 0x1758090 1 0>, \
	<DCC_READ 0x1759010 1 0>, \
	<DCC_READ 0x175A010 1 0>, \
	<DCC_READ 0x175C010 1 0>, \
	<DCC_READ 0x175D010 1 0>, \
	<DCC_READ 0x175E010 1 0>

#define config_dcc_apps_rsc \
    /* APPS PDC Registers */ \
	<DCC_READ 0x0B201020 2 0>, \
	<DCC_READ 0x0B200010 4 0>, \
	<DCC_READ 0x0B220010 4 0>, \
	<DCC_READ 0x0B200900 4 0>, \
	<DCC_READ 0x0B220900 4 0>, \
	<DCC_READ 0x0B201030 1 0>, \
	<DCC_READ 0x0B201204 1 0>, \
	<DCC_READ 0x0B201218 1 0>, \
	<DCC_READ 0x0B20122C 1 0>, \
	<DCC_READ 0x0B201240 1 0>, \
	<DCC_READ 0x0B201254 1 0>, \
	<DCC_READ 0x0B201208 1 0>, \
	<DCC_READ 0x0B20121C 1 0>, \
	<DCC_READ 0x0B201230 1 0>, \
	<DCC_READ 0x0B201244 1 0>, \
	<DCC_READ 0x0B201258 1 0>, \
	<DCC_READ 0x0B204510 1 0>, \
	<DCC_READ 0x0B204514 1 0>, \
	<DCC_READ 0x0B204520 1 0>, \
	<DCC_READ 0x0B211024 1 0>, \
	<DCC_READ 0x0B221024 1 0>, \
	<DCC_READ 0x0B231024 1 0>, \
    /* APPS RSC Registers */ \
	<DCC_READ 0x18220010 1 0>, \
	<DCC_READ 0x18220030 1 0>, \
	<DCC_READ 0x182200D0 1 0>, \
	<DCC_READ 0x18220408 1 0>, \
	<DCC_READ 0x18230408 1 0>

#define config_dcc_misc \
    /* APPS_SHARED_GNOC_HANG_CONFIG */ \
	<DCC_READ 0x17E00434 1 0>, \
	<DCC_READ 0x17E0043C 2 0>, \
    /* APSS_SHARED_WDOG_BITE_INT0_CONFIG */ \
	<DCC_READ 0x17C00038 2 0>, \
    /* APSS_SHARED_GIC_ERR_IPC(GIC 500 error) */ \
	<DCC_READ 0x17C00438 1 0>, \
    /* APSS_SHARED_GNOC_HANG_THRESHOLD_0(MIBU HANG counter threshold) */ \
	<DCC_READ 0x17E0041C 1 0>, \
    /* APSS_SHARED_GNOC_HANG_THRESHOLD_0(PP HANG counter threshold) */ \
	<DCC_READ 0x17E00420 1 0>, \
    /* APSS_SHARED_GNOC_HANG_COUNTER_0 */ \
	<DCC_READ 0x17E00404 1 0>, \
    /* MPM_READ_CNTCV_LO */ \
	<DCC_READ 0xC220000 2 0>, \
    /* secure bite registers */ \
	<DCC_READ 0xC230000 6 0>, \
    /* RPMH_AHB_ERROR_EN */ \
	<DCC_READ 0xC260008 1 0>, \
    /* EPSSTOP_MUC_HANG_IRQ_STS */ \
	<DCC_READ 0x18598014 1 0>, \
    /* IPC CORE */ \
	<DCC_READ 0x4D8634 1 0>, \
	<DCC_READ 0x4D8834 1 0>, \
	<DCC_READ 0x418620 1 0>, \
	<DCC_READ 0x418820 1 0>

#define config_dcc_ddr \
    /* Read the CLKS for SHRM CORE */ \
	<DCC_READ 0x9084208 1 0>, \
	<DCC_READ 0x9084204 1 0>, \
	<DCC_READ 0x9084108 1 0>, \
	<DCC_READ 0x90841C0 1 0>, \
	<DCC_READ 0x10C034 1 0>, \
	<DCC_READ 0x10C038 1 0>, \
	<DCC_READ 0x144018 1 0>, \
    /* Enable clks for SHRM CORE */ \
	<DCC_WRITE 0x90841C0 0x1 0>, \
	<DCC_WRITE 0x10C034 0x1 0>, \
	<DCC_WRITE 0x10C038 0x1 0>, \
	<DCC_WRITE 0x144018 0x1 0>, \
    /* DDR -DCC starts here. */ \
    /* SHRM_CSR_SHRM_CSR */ \
	<DCC_READ 0x9050078 1 0>, \
	<DCC_READ 0x9050110 8 0>, \
    /* DDR_REG_DDR_SS_REGS */ \
	<DCC_READ 0x9080058 2 0>, \
	<DCC_READ 0x90800C8 1 0>, \
	<DCC_READ 0x90800D4 1 0>, \
	<DCC_READ 0x90800E0 1 0>, \
	<DCC_READ 0x90800FC 1 0>, \
	<DCC_READ 0x9084030 1 0>, \
	<DCC_READ 0x9084038 2 0>, \
	<DCC_READ 0x90840E4 1 0>, \
	<DCC_READ 0x90840F4 1 0>, \
	<DCC_READ 0x9084104 2 0>, \
	<DCC_READ 0x9084198 1 0>, \
	<DCC_READ 0x9084804 1 0>, \
	<DCC_READ 0x908480C 1 0>, \
	<DCC_READ 0x9084844 1 0>, \
	<DCC_READ 0x9084850 2 0>, \
	<DCC_READ 0x9084860 3 0>, \
	<DCC_READ 0x9084888 1 0>, \
	<DCC_READ 0x908488c 1 0>, \
	<DCC_READ 0x908409c 1 0>, \
	<DCC_READ 0x90840a0 1 0>, \
	<DCC_READ 0x908426c 1 0>, \
	<DCC_READ 0x908439c 1 0>, \
	<DCC_READ 0x9085124 1 0>, \
    /* New DPCC PLL registers */ \
	<DCC_READ 0x9085134 1 0>, \
	<DCC_READ 0x9085138 1 0>, \
	<DCC_READ 0x9084840 1 0>, \
	<DCC_READ 0x9084834 1 0>, \
	<DCC_READ 0x9085124 1 0>, \
    /* MCC registers */ \
	<DCC_READ 0x90BA280 1 0>, \
	<DCC_READ 0x90BA288 7 0>, \
	<DCC_READ 0x9258610 4 0>, \
	<DCC_READ 0x92D8610 4 0>, \
    /*  LLCC registers */ \
	<DCC_READ 0x9220344 8 0>, \
	<DCC_READ 0x9220370 6 0>, \
	<DCC_READ 0x9220480 1 0>, \
	<DCC_READ 0x9222400 1 0>, \
	<DCC_READ 0x922240C 1 0>, \
	<DCC_READ 0x9223214 2 0>, \
	<DCC_READ 0x9223220 3 0>, \
	<DCC_READ 0x9223308 1 0>, \
	<DCC_READ 0x9223318 1 0>, \
	<DCC_READ 0x9232100 1 0>, \
	<DCC_READ 0x9236040 6 0>, \
	<DCC_READ 0x92360B0 1 0>, \
	<DCC_READ 0x923a004 4 0>, \
	<DCC_READ 0x923E030 2 0>, \
	<DCC_READ 0x9241000 1 0>, \
	<DCC_READ 0x9242028 1 0>, \
	<DCC_READ 0x9242044 3 0>, \
	<DCC_READ 0x9242070 1 0>, \
	<DCC_READ 0x9248030 1 0>, \
	<DCC_READ 0x9248048 8 0>, \
    /* LLCC0 */ \
	<DCC_READ 0x9238030 1 0>, \
	<DCC_READ 0x9238060 1 0>, \
	<DCC_READ 0x9238064 1 0>, \
	<DCC_READ 0x9238074 1 0>, \
	<DCC_READ 0x9238088 1 0>, \
	<DCC_READ 0x92380A0 1 0>, \
	<DCC_READ 0x92380B0 1 0>, \
    /* LLCC1 Registers */ \
	<DCC_READ 0x92A0344 8 0>, \
	<DCC_READ 0x92A0370 6 0>, \
	<DCC_READ 0x92A0480 1 0>, \
	<DCC_READ 0x92A2400 1 0>, \
	<DCC_READ 0x92A240C 1 0>, \
	<DCC_READ 0x92A3214 2 0>, \
	<DCC_READ 0x92A3220 3 0>, \
	<DCC_READ 0x92A3308 1 0>, \
	<DCC_READ 0x92A3318 1 0>, \
	<DCC_READ 0x92B2100 1 0>, \
	<DCC_READ 0x92B6040 6 0>, \
	<DCC_READ 0x92B60B0 1 0>, \
	<DCC_READ 0x92ba004 4 0>, \
	<DCC_READ 0x92BE030 2 0>, \
	<DCC_READ 0x92C1000 1 0>, \
	<DCC_READ 0x92C2028 1 0>, \
	<DCC_READ 0x92C2044 3 0>, \
	<DCC_READ 0x92C2070 1 0>, \
	<DCC_READ 0x92C8030 1 0>, \
	<DCC_READ 0x92C8048 8 0>, \
	<DCC_READ 0x92B8030 1 0>, \
	<DCC_READ 0x92B8060 1 0>, \
	<DCC_READ 0x92B8064 1 0>, \
	<DCC_READ 0x92B8074 1 0>, \
	<DCC_READ 0x92B8088 1 0>, \
	<DCC_READ 0x92B80A0 1 0>, \
	<DCC_READ 0x92B80B0 1 0>, \
	<DCC_READ 0x92C8064 1 0>, \
    /*  Memory controller registers(MC4/5) */ \
	<DCC_READ 0x9270080 1 0>, \
	<DCC_READ 0x9270310 1 0>, \
	<DCC_READ 0x9270400 1 0>, \
	<DCC_READ 0x9270410 6 0>, \
	<DCC_READ 0x9270430 1 0>, \
	<DCC_READ 0x9270440 1 0>, \
	<DCC_READ 0x9270448 1 0>, \
	<DCC_READ 0x92704A0 1 0>, \
	<DCC_READ 0x92704B0 1 0>, \
	<DCC_READ 0x92704B8 2 0>, \
	<DCC_READ 0x92704D0 2 0>, \
	<DCC_READ 0x9271400 1 0>, \
	<DCC_READ 0x9271408 1 0>, \
	<DCC_READ 0x927341C 1 0>, \
	<DCC_READ 0x9273420 1 0>, \
	<DCC_READ 0x92753B0 1 0>, \
	<DCC_READ 0x9275804 1 0>, \
	<DCC_READ 0x9275C18 2 0>, \
	<DCC_READ 0x9275C2C 1 0>, \
	<DCC_READ 0x9275C38 1 0>, \
	<DCC_READ 0x9276418 2 0>, \
	<DCC_READ 0x9279100 1 0>, \
	<DCC_READ 0x9279110 1 0>, \
	<DCC_READ 0x9279120 1 0>, \
	<DCC_READ 0x9279180 2 0>, \
	<DCC_READ 0x92F0080 1 0>, \
	<DCC_READ 0x92F0310 1 0>, \
	<DCC_READ 0x92F0400 1 0>, \
	<DCC_READ 0x92F0410 6 0>, \
	<DCC_READ 0x92F0430 1 0>, \
	<DCC_READ 0x92F0440 1 0>, \
	<DCC_READ 0x92F0448 1 0>, \
	<DCC_READ 0x92F04A0 1 0>, \
	<DCC_READ 0x92F04B0 1 0>, \
	<DCC_READ 0x92F04B8 2 0>, \
	<DCC_READ 0x92F04D0 2 0>, \
	<DCC_READ 0x92F1400 1 0>, \
	<DCC_READ 0x92F1408 1 0>, \
	<DCC_READ 0x92F341C 1 0>, \
	<DCC_READ 0x92F3420 1 0>, \
	<DCC_READ 0x92F53B0 1 0>, \
	<DCC_READ 0x92F5804 1 0>, \
	<DCC_READ 0x92F5C18 2 0>, \
	<DCC_READ 0x92F5C2C 1 0>, \
	<DCC_READ 0x92F5C38 1 0>, \
	<DCC_READ 0x92F6418 2 0>, \
	<DCC_READ 0x92F9100 1 0>, \
	<DCC_READ 0x92F9110 1 0>, \
	<DCC_READ 0x92F9120 1 0>, \
	<DCC_READ 0x92F9180 2 0>, \
    /* CAB MC0 */ \
	<DCC_READ 0x9260080 1 0>, \
	<DCC_READ 0x9260400 1 0>, \
	<DCC_READ 0x9260410 3 0>, \
	<DCC_READ 0x9260420 2 0>, \
	<DCC_READ 0x9260430 1 0>, \
	<DCC_READ 0x9260440 1 0>, \
	<DCC_READ 0x9260448 1 0>, \
	<DCC_READ 0x92604A0 1 0>, \
	<DCC_READ 0x92604B0 1 0>, \
	<DCC_READ 0x92604B8 2 0>, \
	<DCC_READ 0x92604D0 2 0>, \
	<DCC_READ 0x9261400 1 0>, \
	<DCC_READ 0x9263410 1 0>, \
	<DCC_READ 0x92653B0 1 0>, \
	<DCC_READ 0x9265804 1 0>, \
	<DCC_READ 0x9265B1C 1 0>, \
	<DCC_READ 0x9265B2C 1 0>, \
	<DCC_READ 0x9265B38 1 0>, \
	<DCC_READ 0x9269100 1 0>, \
	<DCC_READ 0x9269108 1 0>, \
	<DCC_READ 0x9269110 1 0>, \
	<DCC_READ 0x9269118 1 0>, \
	<DCC_READ 0x9269120 1 0>, \
	<DCC_READ 0x9269180 2 0>, \
    /* CAB MC1 */ \
	<DCC_READ 0x92E0080 1 0>, \
	<DCC_READ 0x92E0400 1 0>, \
	<DCC_READ 0x92E0410 3 0>, \
	<DCC_READ 0x92E0420 2 0>, \
	<DCC_READ 0x92E0430 1 0>, \
	<DCC_READ 0x92E0440 1 0>, \
	<DCC_READ 0x92E0448 1 0>, \
	<DCC_READ 0x92E04A0 1 0>, \
	<DCC_READ 0x92E04B0 1 0>, \
	<DCC_READ 0x92E04B8 2 0>, \
	<DCC_READ 0x92E04D0 2 0>, \
	<DCC_READ 0x92E1400 1 0>, \
	<DCC_READ 0x92E3410 1 0>, \
	<DCC_READ 0x92E53B0 1 0>, \
	<DCC_READ 0x92E5804 1 0>, \
	<DCC_READ 0x92E5B1C 1 0>, \
	<DCC_READ 0x92E5B2C 1 0>, \
	<DCC_READ 0x92E5B38 1 0>, \
	<DCC_READ 0x92E9100 1 0>, \
	<DCC_READ 0x92e9108 1 0>, \
	<DCC_READ 0x92E9110 1 0>, \
	<DCC_READ 0x92E9118 1 0>, \
	<DCC_READ 0x92E9120 1 0>, \
	<DCC_READ 0x92E9180 2 0>, \
    /*  DDRPHY */ \
	<DCC_READ 0x96B0868 1 0>, \
	<DCC_READ 0x96B0870 1 0>, \
	<DCC_READ 0x96B1004 1 0>, \
	<DCC_READ 0x96B100C 1 0>, \
	<DCC_READ 0x96B1014 1 0>, \
	<DCC_READ 0x96B1204 1 0>, \
	<DCC_READ 0x96B120C 1 0>, \
	<DCC_READ 0x96B1214 1 0>, \
	<DCC_READ 0x96B1504 1 0>, \
	<DCC_READ 0x96B150C 1 0>, \
	<DCC_READ 0x96B1514 1 0>, \
	<DCC_READ 0x96B1604 1 0>, \
	<DCC_READ 0x96B8100 1 0>, \
	<DCC_READ 0x96B813C 1 0>, \
	<DCC_READ 0x96B8500 1 0>, \
	<DCC_READ 0x96B853C 1 0>, \
	<DCC_READ 0x96B8A04 1 0>, \
	<DCC_READ 0x96B8A18 1 0>, \
	<DCC_READ 0x96B8EA8 1 0>, \
	<DCC_READ 0x96B9044 1 0>, \
	<DCC_READ 0x96B904C 1 0>, \
	<DCC_READ 0x96B9054 1 0>, \
	<DCC_READ 0x96B905C 1 0>, \
	<DCC_READ 0x96B910C 2 0>, \
	<DCC_READ 0x96B9204 1 0>, \
	<DCC_READ 0x96B920C 1 0>, \
	<DCC_READ 0x96B9238 1 0>, \
	<DCC_READ 0x96B9240 1 0>, \
	<DCC_READ 0x96B926C 1 0>, \
	<DCC_READ 0x96B9394 1 0>, \
	<DCC_READ 0x96B939C 1 0>, \
	<DCC_READ 0x96B9704 1 0>, \
	<DCC_READ 0x96B970C 1 0>, \
	<DCC_READ 0x96F0868 1 0>, \
	<DCC_READ 0x96F0870 1 0>, \
	<DCC_READ 0x96F1004 1 0>, \
	<DCC_READ 0x96F100C 1 0>, \
	<DCC_READ 0x96F1014 1 0>, \
	<DCC_READ 0x96F1204 1 0>, \
	<DCC_READ 0x96F120C 1 0>, \
	<DCC_READ 0x96F1214 1 0>, \
	<DCC_READ 0x96F1504 1 0>, \
	<DCC_READ 0x96F150C 1 0>, \
	<DCC_READ 0x96F1514 1 0>, \
	<DCC_READ 0x96F1604 1 0>, \
	<DCC_READ 0x96F8100 1 0>, \
	<DCC_READ 0x96F813C 1 0>, \
	<DCC_READ 0x96F8500 1 0>, \
	<DCC_READ 0x96F853C 1 0>, \
	<DCC_READ 0x96F8A04 1 0>, \
	<DCC_READ 0x96F8A18 1 0>, \
	<DCC_READ 0x96F8EA8 1 0>, \
	<DCC_READ 0x96F9044 1 0>, \
	<DCC_READ 0x96F904C 1 0>, \
	<DCC_READ 0x96F9054 1 0>, \
	<DCC_READ 0x96F905C 1 0>, \
	<DCC_READ 0x96F910C 2 0>, \
	<DCC_READ 0x96F9204 1 0>, \
	<DCC_READ 0x96F920C 1 0>, \
	<DCC_READ 0x96F9238 1 0>, \
	<DCC_READ 0x96F9240 1 0>, \
	<DCC_READ 0x96F926C 1 0>, \
	<DCC_READ 0x96F9394 1 0>, \
	<DCC_READ 0x96F939C 1 0>, \
	<DCC_READ 0x96F9704 1 0>, \
	<DCC_READ 0x96F970C 1 0>, \
    /*  GEMNOC */ \
	<DCC_READ 0x9130100 3 0>, \
	<DCC_READ 0x9170100 3 0>, \
	<DCC_READ 0x91DD100 4 0>, \
	<DCC_READ 0x91DF100 1 0>, \
    /* Pimem */ \
	<DCC_READ 0x610110 5 0>, \
    /* LLCC Registers */ \
	<DCC_READ 0x9230010 1 0>, \
	<DCC_READ 0x9230020 1 0>, \
	<DCC_READ 0x9230030 1 0>, \
	<DCC_READ 0x9230040 1 0>, \
	<DCC_READ 0x92B0010 1 0>, \
	<DCC_READ 0x92B0020 1 0>, \
	<DCC_READ 0x92B0030 1 0>, \
	<DCC_READ 0x92B0040 1 0>, \
	<DCC_READ 0x9232050 1 0>, \
	<DCC_READ 0x923605C 2 0>, \
	<DCC_READ 0x92360A0 1 0>, \
	<DCC_READ 0x923A018 2 0>, \
	<DCC_READ 0x92B2050 1 0>, \
	<DCC_READ 0x92B605C 2 0>, \
	<DCC_READ 0x92B60A0 1 0>, \
	<DCC_READ 0x92BA018 2 0>, \
	<DCC_READ 0x9222404 2 0>, \
	<DCC_READ 0x9222410 1 0>, \
	<DCC_READ 0x9238004 1 0>, \
	<DCC_READ 0x9238014 1 0>, \
	<DCC_READ 0x923805C 1 0>, \
	<DCC_READ 0x923A014 1 0>, \
	<DCC_READ 0x92A2404 2 0>, \
	<DCC_READ 0x92A2410 1 0>, \
	<DCC_READ 0x92B8004 1 0>, \
	<DCC_READ 0x92B8014 1 0>, \
	<DCC_READ 0x92B805C 1 0>, \
	<DCC_READ 0x92BA014 1 0>, \
	/*  Delete SHRM Core dcc regs because SDI 1st timeout occurs on entering Ramdump on user/userdebug build */ \
	/*  If need to check SHRM Core regs, re-enable reg in dcc list & debug policy including jtag debug enabled */ \
	/*  SHRM Core \
	<DCC_WRITE 0x06E0A00C 0x00600007 1>, \
	<DCC_WRITE 0x06E0A01C 0x00136800 1>, \
	<DCC_READ 0x06E0A014 1 1>, \
	<DCC_WRITE 0x06E0A01C 0x00136810 1>, \
	<DCC_READ 0x06E0A014 1 1>, \
	<DCC_WRITE 0x06E0A01C 0x00136820 1>, \
	<DCC_READ 0x06E0A014 1 1>, \
	<DCC_WRITE 0x06E0A01C 0x00136830 1>, \
	<DCC_READ 0x06E0A014 1 1>, \
	<DCC_WRITE 0x06E0A01C 0x00136840 1>, \
	<DCC_READ 0x06E0A014 1 1>, \
	<DCC_WRITE 0x06E0A01C 0x00136850 1>, \
	<DCC_READ 0x06E0A014 1 1>, \
	<DCC_WRITE 0x06E0A01C 0x00136860 1>, \
	<DCC_READ 0x06E0A014 1 1>, \
	<DCC_WRITE 0x06E0A01C 0x00136870 1>, \
	<DCC_READ 0x06E0A014 1 1>, \
	<DCC_WRITE 0x06E0A01C 0x0003e9a0 1>, \
	<DCC_WRITE 0x06E0A01C 0x001368a0 1>, \
	<DCC_READ 0x06E0A014 1 1>, \
	<DCC_WRITE 0x06E0A01C 0x0003c0a0 1>, \
	<DCC_WRITE 0x06E0A01C 0x001368a0 1>, \
	<DCC_READ 0x06E0A014 1 1>, \
	<DCC_WRITE 0x06E0A01C 0x0003d1a0 1>, \
	<DCC_WRITE 0x06E0A01C 0x001368a0 1>, \
	<DCC_READ 0x06E0A014 1 1>, \
	<DCC_WRITE 0x06E0A01C 0x0003d2a0 1>, \
	<DCC_WRITE 0x06E0A01C 0x001368a0 1>, \
	<DCC_READ 0x06E0A014 1 1>, \
	<DCC_WRITE 0x06E0A01C 0x0003d5a0 1>, \
	<DCC_WRITE 0x06E0A01C 0x001368a0 1>, \
	<DCC_READ 0x06E0A014 1 1>, \
	<DCC_WRITE 0x06E0A01C 0x0003d6a0 1>, \
	<DCC_WRITE 0x06E0A01C 0x001368a0 1>, \
	<DCC_READ 0x06E0A014 1 1>, \
	<DCC_WRITE 0x06E0A01C 0x0003e8a0 1>, \
	<DCC_WRITE 0x06E0A01C 0x001368a0 1>, \
	<DCC_READ 0x06E0A014 1 1>, \
	<DCC_WRITE 0x06E0A01C 0x0003eea0 1>, \
	<DCC_WRITE 0x06E0A01C 0x001368a0 1>, \
	<DCC_READ 0x06E0A014 1 1>, \
	<DCC_WRITE 0x06E0A01C 0x0003b1a0 1>, \
	<DCC_WRITE 0x06E0A01C 0x001368a0 1>, \
	<DCC_READ 0x06E0A014 1 1>, \
	<DCC_WRITE 0x06E0A01C 0x0003b2a0 1>, \
	<DCC_WRITE 0x06E0A01C 0x001368a0 1>, \
	<DCC_READ 0x06E0A014 1 1>, \
	<DCC_WRITE 0x06E0A01C 0x0003b5a0 1>, \
	<DCC_WRITE 0x06E0A01C 0x001368a0 1>, \
	<DCC_READ 0x06E0A014 1 1>, \
	<DCC_WRITE 0x06E0A01C 0x0003b6a0 1>, \
	<DCC_WRITE 0x06E0A01C 0x001368a0 1>, \
	<DCC_READ 0x06E0A014 1 1>, \
	<DCC_WRITE 0x06E0A01C 0x0003c2a0 1>, \
	<DCC_WRITE 0x06E0A01C 0x001368a0 1>, \
	<DCC_READ 0x06E0A014 1 1>, \
	<DCC_WRITE 0x06E0A01C 0x0003c5a0 1>, \
	<DCC_WRITE 0x06E0A01C 0x001368a0 1>, \
	<DCC_READ 0x06E0A014 1 1>, \
	<DCC_WRITE 0x06E0A01C 0x0003c6a0 1>, \
	<DCC_WRITE 0x06E0A01C 0x001368a0 1>, \
	<DCC_READ 0x06E0A014 1 1>, \
	<DCC_WRITE 0x06E0A014 0x0002000c 1>, \
	<DCC_WRITE 0x06E0A01C 0x000368b0 1>, \
	<DCC_WRITE 0x06E0A01C 0x00000ba8 1>, \
	<DCC_WRITE 0x06E0A01C 0x0013B6A0 1>, \
	<DCC_WRITE 0x06E0A01C 0x00F1E000 1>, \
	<DCC_WRITE 0x06E0A008 0x00000007 1>, \
	<DCC_READ 0x09067E00 124 0>,      */ \
    /* SHRM CSR Registers */ \
	<DCC_READ 0x905000C 1 0>, \
	<DCC_READ 0x9050948 1 0>, \
	<DCC_READ 0x9050078 1 0>, \
	<DCC_READ 0x9050008 1 0>, \
    /* Misc registers */ \
    /* DPCC_REG_DPCC_GCC_CLK_ON_STATUS */ \
	<DCC_READ 0x9084878 1 0>, \
    /* SHRM_CSR_SHRM_RCI_CTRL */ \
	<DCC_READ 0x9050950 1 0>, \
    /* QHM_SHRM_MPU_XPU3_QAD1_EAR1 */ \
	<DCC_READ 0x90C2884 1 0>

#define config_dcc_modem_rsc \
    /* Modem PDC Registers */ \
	<DCC_READ 0xB2C4520 1 0>, \
	<DCC_READ 0xB2C1020 2 0>, \
	<DCC_READ 0xB2C1030 1 0>, \
	<DCC_READ 0xB2C1200 1 0>, \
	<DCC_READ 0xB2C1214 1 0>, \
	<DCC_READ 0xB2C1228 1 0>, \
	<DCC_READ 0xB2C123C 1 0>, \
	<DCC_READ 0xB2C1250 1 0>, \
	<DCC_READ 0xB2C1204 1 0>, \
	<DCC_READ 0xB2C1218 1 0>, \
	<DCC_READ 0xB2C122C 1 0>, \
	<DCC_READ 0xB2C1240 1 0>, \
	<DCC_READ 0xB2C1254 1 0>, \
	<DCC_READ 0xB2C1208 1 0>, \
	<DCC_READ 0xB2C121C 1 0>, \
	<DCC_READ 0xB2C1230 1 0>, \
	<DCC_READ 0xB2C1244 1 0>, \
	<DCC_READ 0xB2C1258 1 0>, \
	<DCC_READ 0xB2C4510 2 0>, \
	<DCC_READ 0xB2C0010 2 0>, \
	<DCC_READ 0xB2C0900 2 0>, \
	<DCC_READ 0x04082028 1 0>, \
	<DCC_READ 0x18A00C 1 0>, \
	<DCC_READ 0x04080044 1 0>, \
	<DCC_READ 0x04080304 1 0>, \
	<DCC_READ 0x41A802C 1 0>, \
    /* Modem RSCp Registers */ \
	<DCC_READ 0x4200010 3 0>, \
	<DCC_READ 0x4200030 1 0>, \
	<DCC_READ 0x4200038 1 0>, \
	<DCC_READ 0x4200040 1 0>, \
	<DCC_READ 0x4200048 1 0>, \
	<DCC_READ 0x42000D0 1 0>, \
	<DCC_READ 0x4200210 1 0>, \
	<DCC_READ 0x4200230 1 0>, \
	<DCC_READ 0x4200250 1 0>, \
	<DCC_READ 0x4200270 1 0>, \
	<DCC_READ 0x4200290 1 0>, \
	<DCC_READ 0x42002B0 1 0>, \
	<DCC_READ 0x4200208 1 0>, \
	<DCC_READ 0x4200228 1 0>, \
	<DCC_READ 0x4200248 1 0>, \
	<DCC_READ 0x4200268 1 0>, \
	<DCC_READ 0x4200288 1 0>, \
	<DCC_READ 0x42002A8 1 0>, \
	<DCC_READ 0x420020C 1 0>, \
	<DCC_READ 0x420022C 1 0>, \
	<DCC_READ 0x420024C 1 0>, \
	<DCC_READ 0x420026C 1 0>, \
	<DCC_READ 0x420028C 1 0>, \
	<DCC_READ 0x42002AC 1 0>, \
	<DCC_READ 0x4200400 3 0>, \
	<DCC_READ 0x4200D04 1 0>, \
    /* Modem RSCc Registers */ \
	<DCC_READ 0x4130010 3 0>, \
	<DCC_READ 0x4130210 1 0>, \
	<DCC_READ 0x4130230 1 0>, \
	<DCC_READ 0x4130250 1 0>, \
	<DCC_READ 0x4130270 1 0>, \
	<DCC_READ 0x4130290 1 0>, \
	<DCC_READ 0x41302B0 1 0>, \
	<DCC_READ 0x4130208 1 0>, \
	<DCC_READ 0x4130228 1 0>, \
	<DCC_READ 0x4130248 1 0>, \
	<DCC_READ 0x4130268 1 0>, \
	<DCC_READ 0x4130288 1 0>, \
	<DCC_READ 0x41302A8 1 0>, \
	<DCC_READ 0x413020C 1 0>, \
	<DCC_READ 0x413022C 1 0>, \
	<DCC_READ 0x413024C 1 0>, \
	<DCC_READ 0x413026C 1 0>, \
	<DCC_READ 0x413028C 1 0>, \
	<DCC_READ 0x41302AC 1 0>, \
	<DCC_READ 0x4130400 3 0>

#define config_dcc_lpass_rsc  \
    /* LPASS PDC Registers */ \
	<DCC_READ 0xB254520 1 0>, \
	<DCC_READ 0xB251020 2 0>, \
	<DCC_READ 0xB251030 1 0>, \
	<DCC_READ 0xB251200 1 0>, \
	<DCC_READ 0xB251214 1 0>, \
	<DCC_READ 0xB251228 1 0>, \
	<DCC_READ 0xB25123C 1 0>, \
	<DCC_READ 0xB251250 1 0>, \
	<DCC_READ 0xB251204 1 0>, \
	<DCC_READ 0xB251218 1 0>, \
	<DCC_READ 0xB25122C 1 0>, \
	<DCC_READ 0xB251240 1 0>, \
	<DCC_READ 0xB251254 1 0>, \
	<DCC_READ 0xB251208 1 0>, \
	<DCC_READ 0xB25121C 1 0>, \
	<DCC_READ 0xB251230 1 0>, \
	<DCC_READ 0xB251244 1 0>, \
	<DCC_READ 0xB251258 1 0>, \
	<DCC_READ 0xB254510 2 0>, \
	<DCC_READ 0xB250010 2 0>, \
	<DCC_READ 0xB250900 2 0>, \
	<DCC_READ 0x03002028 1 0>, \
    /* LPASS RSCp registers */ \
	<DCC_READ 0x03500010 3 0>, \
	<DCC_READ 0x03500030 1 0>, \
	<DCC_READ 0x03500038 1 0>, \
	<DCC_READ 0x03500040 1 0>, \
	<DCC_READ 0x03500048 1 0>, \
	<DCC_READ 0x035000D0 1 0>, \
	<DCC_READ 0x03500210 1 0>, \
	<DCC_READ 0x03500230 1 0>, \
	<DCC_READ 0x03500250 1 0>, \
	<DCC_READ 0x03500270 1 0>, \
	<DCC_READ 0x03500290 1 0>, \
	<DCC_READ 0x035002B0 1 0>, \
	<DCC_READ 0x03500208 1 0>, \
	<DCC_READ 0x03500228 1 0>, \
	<DCC_READ 0x03500248 1 0>, \
	<DCC_READ 0x03500268 1 0>, \
	<DCC_READ 0x03500288 1 0>, \
	<DCC_READ 0x035002A8 1 0>, \
	<DCC_READ 0x0350020C 1 0>, \
	<DCC_READ 0x0350022C 1 0>, \
	<DCC_READ 0x0350024C 1 0>, \
	<DCC_READ 0x0350026C 1 0>, \
	<DCC_READ 0x0350028C 1 0>, \
	<DCC_READ 0x035002AC 1 0>, \
	<DCC_READ 0x03500400 3 0>, \
	<DCC_READ 0x03500D04 1 0>, \
    /* LPASS RSCc registers */ \
	<DCC_READ 0x030B0010 3 0>, \
	<DCC_READ 0x030B0210 1 0>, \
	<DCC_READ 0x030B0230 1 0>, \
	<DCC_READ 0x030B0250 1 0>, \
	<DCC_READ 0x030B0270 1 0>, \
	<DCC_READ 0x030B0290 1 0>, \
	<DCC_READ 0x030B02B0 1 0>, \
	<DCC_READ 0x030B0208 1 0>, \
	<DCC_READ 0x030B0228 1 0>, \
	<DCC_READ 0x030B0248 1 0>, \
	<DCC_READ 0x030B0268 1 0>, \
	<DCC_READ 0x030B0288 1 0>, \
	<DCC_READ 0x030B02A8 1 0>, \
	<DCC_READ 0x030B020C 1 0>, \
	<DCC_READ 0x030B022C 1 0>, \
	<DCC_READ 0x030B024C 1 0>, \
	<DCC_READ 0x030B026C 1 0>, \
	<DCC_READ 0x030B028C 1 0>, \
	<DCC_READ 0x030B02AC 1 0>, \
	<DCC_READ 0x030B0400 3 0>

#define config_dcc_nsp_rsc \
    /* Turing QDSP PDC Registers */ \
	<DCC_READ 0xB2B4520 1 0>, \
	<DCC_READ 0xB2B1020 2 0>, \
	<DCC_READ 0xB2B1030 1 0>, \
	<DCC_READ 0xB2B1200 1 0>, \
	<DCC_READ 0xB2B1214 1 0>, \
	<DCC_READ 0xB2B1228 1 0>, \
	<DCC_READ 0xB2B123C 1 0>, \
	<DCC_READ 0xB2B1250 1 0>, \
	<DCC_READ 0xB2B1204 1 0>, \
	<DCC_READ 0xB2B1218 1 0>, \
	<DCC_READ 0xB2B122C 1 0>, \
	<DCC_READ 0xB2B1240 1 0>, \
	<DCC_READ 0xB2B1254 1 0>, \
	<DCC_READ 0xB2B1208 1 0>, \
	<DCC_READ 0xB2B121C 1 0>, \
	<DCC_READ 0xB2B1230 1 0>, \
	<DCC_READ 0xB2B1244 1 0>, \
	<DCC_READ 0xB2B1258 1 0>, \
	<DCC_READ 0xB2B4510 2 0>, \
	<DCC_READ 0xB2B0010 1 0>, \
	<DCC_READ 0xB2B0900 1 0>, \
	<DCC_READ 0xA302028 1 0>, \
    /* Turing QDSP RSCp registers */ \
	<DCC_READ 0xA0A4010 3 0>, \
	<DCC_READ 0xA0A4030 1 0>, \
	<DCC_READ 0xA0A4038 1 0>, \
	<DCC_READ 0xA0A4040 2 0>, \
	<DCC_READ 0xA0A40D0 1 0>, \
	<DCC_READ 0xA0A4210 1 0>, \
	<DCC_READ 0xA0A4230 1 0>, \
	<DCC_READ 0xA0A4250 1 0>, \
	<DCC_READ 0xA0A4270 1 0>, \
	<DCC_READ 0xA0A4290 1 0>, \
	<DCC_READ 0xA0A42B0 1 0>, \
	<DCC_READ 0xA0A4208 1 0>, \
	<DCC_READ 0xA0A4228 1 0>, \
	<DCC_READ 0xA0A4248 1 0>, \
	<DCC_READ 0xA0A4268 1 0>, \
	<DCC_READ 0xA0A4288 1 0>, \
	<DCC_READ 0xA0A42A8 1 0>, \
	<DCC_READ 0xA0A420C 1 0>, \
	<DCC_READ 0xA0A422C 1 0>, \
	<DCC_READ 0xA0A424C 1 0>, \
	<DCC_READ 0xA0A426C 1 0>, \
	<DCC_READ 0xA0A428C 1 0>, \
	<DCC_READ 0xA0A42AC 1 0>, \
	<DCC_READ 0xA0A4400 2 0>, \
	<DCC_READ 0xA0A4D04 1 0>, \
    /* Turing QDSP RSCc registers */ \
	<DCC_READ 0xA3B0010 3 0>, \
	<DCC_READ 0xA3B0210 1 0>, \
	<DCC_READ 0xA3B0230 1 0>, \
	<DCC_READ 0xA3B0250 1 0>, \
	<DCC_READ 0xA3B0270 1 0>, \
	<DCC_READ 0xA3B0290 1 0>, \
	<DCC_READ 0xA3B02B0 1 0>, \
	<DCC_READ 0xA3B0208 1 0>, \
	<DCC_READ 0xA3B0228 1 0>, \
	<DCC_READ 0xA3B0248 1 0>, \
	<DCC_READ 0xA3B0268 1 0>, \
	<DCC_READ 0xA3B0288 1 0>, \
	<DCC_READ 0xA3B02A8 1 0>, \
	<DCC_READ 0xA3B020C 1 0>, \
	<DCC_READ 0xA3B022C 1 0>, \
	<DCC_READ 0xA3B024C 1 0>, \
	<DCC_READ 0xA3B026C 1 0>, \
	<DCC_READ 0xA3B028C 1 0>, \
	<DCC_READ 0xA3B02AC 1 0>, \
	<DCC_READ 0xA3B0400 3 0>

#define config_dcc_lpass_cdsp_tunning \
    /* LPASS_RSCC_TCS_AMC_MODE_IRQ */ \
	<DCC_READ 0x3500D00 3 0>, \
    /*  LPASS_RSCC_TCS */ \
	<DCC_READ 0x3500D10 4 0>, \
	<DCC_READ 0x3500FB0 4 0>, \
	<DCC_READ 0x3501250 4 0>, \
	<DCC_READ 0x35014F0 4 0>, \
	<DCC_READ 0x3501790 4 0>, \
	<DCC_READ 0x3501A30 4 0>, \
	<DCC_READ 0x3503D44 4 0>, \
	<DCC_READ 0x35000D0 3 0>, \
	<DCC_READ 0x3500100 1 0>, \
	<DCC_READ 0x3500D3C 1 0>, \
    /* CDSP */ \
	<DCC_READ 0xA0A40D0 3 0>, \
	<DCC_READ 0xA0A4100 1 0>, \
	<DCC_READ 0xA0A4D3C 1 0>, \
	<DCC_READ 0xA0A7D44 4 0>, \
	<DCC_READ 0xA0A4D00 3 0>

#define config_dcc_wpss_rsc \
	<DCC_READ 0x8A02028 1 0>, \
	<DCC_READ 0x8b00000 1 0>, \
	<DCC_READ 0x8b00004 1 0>, \
	<DCC_READ 0x8b00010 1 0>, \
	<DCC_READ 0x8b00014 1 0>, \
	<DCC_READ 0x8b00018 1 0>, \
	<DCC_READ 0x8b0001c 1 0>, \
	<DCC_READ 0x8b00020 1 0>, \
	<DCC_READ 0x8b00024 1 0>, \
	<DCC_READ 0x8b00028 1 0>, \
	<DCC_READ 0x8b0002c 1 0>, \
	<DCC_READ 0x8b00030 1 0>, \
	<DCC_READ 0x8b00034 1 0>, \
	<DCC_READ 0x8b00038 1 0>, \
	<DCC_READ 0x8b0003c 1 0>, \
	<DCC_READ 0x8b00040 1 0>, \
	<DCC_READ 0x8b00044 1 0>, \
	<DCC_READ 0x8b00048 1 0>, \
	<DCC_READ 0x8b000d0 1 0>, \
	<DCC_READ 0x8b000d8 1 0>, \
	<DCC_READ 0x8b00100 1 0>, \
	<DCC_READ 0x8b00104 1 0>, \
	<DCC_READ 0x8b00108 1 0>, \
	<DCC_READ 0x8b00200 1 0>, \
	<DCC_READ 0x8b00204 1 0>, \
	<DCC_READ 0x8b00224 1 0>, \
	<DCC_READ 0x8b00244 1 0>, \
	<DCC_READ 0x8b00264 1 0>, \
	<DCC_READ 0x8b00284 1 0>, \
	<DCC_READ 0x8b002a4 1 0>, \
	<DCC_READ 0x8b00208 1 0>, \
	<DCC_READ 0x8b00228 1 0>, \
	<DCC_READ 0x8b00248 1 0>, \
	<DCC_READ 0x8b00268 1 0>, \
	<DCC_READ 0x8b00288 1 0>, \
	<DCC_READ 0x8b002a8 1 0>, \
	<DCC_READ 0x8b0020c 1 0>, \
	<DCC_READ 0x8b0022c 1 0>, \
	<DCC_READ 0x8b0024c 1 0>, \
	<DCC_READ 0x8b0026c 1 0>, \
	<DCC_READ 0x8b0028c 1 0>, \
	<DCC_READ 0x8b002ac 1 0>, \
	<DCC_READ 0x8b00210 1 0>, \
	<DCC_READ 0x8b00230 1 0>, \
	<DCC_READ 0x8b00250 1 0>, \
	<DCC_READ 0x8b00270 1 0>, \
	<DCC_READ 0x8b00290 1 0>, \
	<DCC_READ 0x8b002b0 1 0>, \
	<DCC_READ 0x8b00400 1 0>, \
	<DCC_READ 0x8b00404 1 0>, \
	<DCC_READ 0x8b00408 1 0>, \
	<DCC_READ 0x8b00460 1 0>, \
	<DCC_READ 0x8b00464 1 0>, \
	<DCC_READ 0x8b004a0 1 0>, \
	<DCC_READ 0x8b004a4 1 0>, \
	<DCC_READ 0x8b004a8 1 0>, \
	<DCC_READ 0x8b004ac 1 0>, \
	<DCC_READ 0x8b004b0 1 0>, \
	<DCC_READ 0x8b004b4 1 0>, \
	<DCC_READ 0x8b004b8 1 0>, \
	<DCC_READ 0x8ab0000 1 0>, \
	<DCC_READ 0x8ab0004 1 0>, \
	<DCC_READ 0x8ab0010 1 0>, \
	<DCC_READ 0x8ab0014 1 0>, \
	<DCC_READ 0x8ab0018 1 0>, \
	<DCC_READ 0x8ab00d0 1 0>, \
	<DCC_READ 0x8ab00d8 1 0>, \
	<DCC_READ 0x8ab0100 1 0>, \
	<DCC_READ 0x8ab0104 1 0>, \
	<DCC_READ 0x8ab0108 1 0>, \
	<DCC_READ 0x8ab0200 1 0>, \
	<DCC_READ 0x8ab0204 1 0>, \
	<DCC_READ 0x8ab0224 1 0>, \
	<DCC_READ 0x8ab0244 1 0>, \
	<DCC_READ 0x8ab0264 1 0>, \
	<DCC_READ 0x8ab0284 1 0>, \
	<DCC_READ 0x8ab02a4 1 0>, \
	<DCC_READ 0x8ab0208 1 0>, \
	<DCC_READ 0x8ab0228 1 0>, \
	<DCC_READ 0x8ab0248 1 0>, \
	<DCC_READ 0x8ab0268 1 0>, \
	<DCC_READ 0x8ab0288 1 0>, \
	<DCC_READ 0x8ab02a8 1 0>, \
	<DCC_READ 0x8ab020c 1 0>, \
	<DCC_READ 0x8ab022c 1 0>, \
	<DCC_READ 0x8ab024c 1 0>, \
	<DCC_READ 0x8ab026c 1 0>, \
	<DCC_READ 0x8ab028c 1 0>, \
	<DCC_READ 0x8ab02ac 1 0>, \
	<DCC_READ 0x8ab0210 1 0>, \
	<DCC_READ 0x8ab0230 1 0>, \
	<DCC_READ 0x8ab0250 1 0>, \
	<DCC_READ 0x8ab0270 1 0>, \
	<DCC_READ 0x8ab0290 1 0>, \
	<DCC_READ 0x8ab02b0 1 0>, \
	<DCC_READ 0x8ab0400 1 0>, \
	<DCC_READ 0x8ab0404 1 0>, \
	<DCC_READ 0x8ab0408 1 0>, \
	<DCC_READ 0x8ab0460 1 0>, \
	<DCC_READ 0x8ab0464 1 0>, \
	<DCC_READ 0x8ab04a0 1 0>, \
	<DCC_READ 0x8ab04a4 1 0>, \
	<DCC_READ 0x8ab04a8 1 0>, \
	<DCC_READ 0x8ab04ac 1 0>, \
	<DCC_READ 0x8ab04b0 1 0>, \
	<DCC_READ 0x8ab04b4 1 0>, \
	<DCC_READ 0x8ab04b8 1 0>

#define config_dcc_video_noc \
	<DCC_READ 0xAA10504 1 0>, \
	<DCC_READ 0xAA10508 1 0>, \
	<DCC_READ 0xAA10510 1 0>, \
	<DCC_READ 0xAA10520 1 0>, \
	<DCC_READ 0xAA10524 1 0>, \
	<DCC_READ 0xAA10528 1 0>, \
	<DCC_READ 0xAA1052C 1 0>, \
	<DCC_READ 0xAA10530 1 0>, \
	<DCC_READ 0xAA10534 1 0>, \
	<DCC_READ 0xAA10538 1 0>, \
	<DCC_READ 0xAA1053C 1 0>, \
	<DCC_READ 0xAA10300 1 0>, \
	<DCC_READ 0xAA10010 1 0>, \
	<DCC_READ 0xAA10020 1 0>

&dcc {
	link_list@6 {
		qcom,data-sink = "sram";
		qcom,curr-link-list = <6>;
		qcom,link-list =
			config_dcc_pcu,
			config_dcc_epss,
			config_dcc_pimem,
			config_dcc_core,
			//enable_dcc_pll_status,
			config_dcc_gemnoc,
			config_dcc_tsens,
			config_dcc_spmi,
			config_dcc_gpu,
			config_sysnoc,
			config_aggrenoc,
			config_dcc_gcc;
	};

	link_list@4 {
		qcom,data-sink = "sram";
		qcom,curr-link-list = <4>;
		qcom,link-list =
			config_confignoc,
			config_dcc_limits,
			config_dcc_gic,
			config_mmssnoc,
			config_dcc_apps_rsc,
			config_dcc_misc,
			config_dcc_ddr;
	};

	link_list@3 {
		qcom,data-sink = "sram";
		qcom,curr-link-list = <3>;
		qcom,link-list =
			//dcc_async_package,
			config_dcc_modem_rsc,
			config_dcc_lpass_rsc,
			config_dcc_nsp_rsc,
			config_dcc_lpass_cdsp_tunning,
			config_dcc_wpss_rsc,
			config_dcc_video_noc;
	};

	link_list1 {
		qcom,curr-link-list = <0xFF>;
	};

	link_list2 {
		qcom,curr-link-list = <0xFF>;
	};

	link_list3 {
		qcom,curr-link-list = <0xFF>;
	};
};
	
